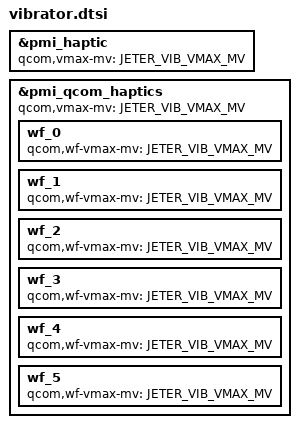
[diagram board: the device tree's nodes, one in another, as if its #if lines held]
#define JETER_VIB_VMAX_MV 3000

#if !defined(CONFIG_INPUT_QTI_HAPTICS) || defined(CONFIG_PARSE_ANDROIDBOOT_MODE)
&pmi_haptic {
	qcom,vmax-mv = <JETER_VIB_VMAX_MV>;
	/delete-property/ qcom,en-brake; /* disable internal reverse braking */
	/delete-property/ qcom,brake-pattern; /* disable brake pattern */
};
#endif

#ifdef CONFIG_INPUT_QTI_HAPTICS
&pmi_qcom_haptics {
	qcom,vmax-mv = <JETER_VIB_VMAX_MV>;
	wf_0 { qcom,wf-vmax-mv = <JETER_VIB_VMAX_MV>; };
	wf_1 { qcom,wf-vmax-mv = <JETER_VIB_VMAX_MV>; };
	wf_2 { qcom,wf-vmax-mv = <JETER_VIB_VMAX_MV>; };
	wf_3 { qcom,wf-vmax-mv = <JETER_VIB_VMAX_MV>; };
	wf_4 { qcom,wf-vmax-mv = <JETER_VIB_VMAX_MV>; };
	wf_5 { qcom,wf-vmax-mv = <JETER_VIB_VMAX_MV>; };
};
#endif
